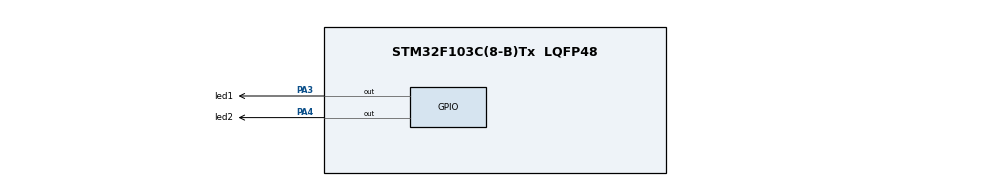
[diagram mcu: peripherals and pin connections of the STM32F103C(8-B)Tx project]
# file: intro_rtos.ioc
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Mcu.Family=STM32F1
FREERTOS.Tasks01=ledBlink01,24,128,StartDefaultTask,Default,NULL,Dynamic,NULL,NULL;ledBlink02,8,128,StartTask02,Default,NULL,Dynamic,NULL,NULL
ProjectManager.StackSize=0x400
VP_FREERTOS_VS_CMSIS_V2.Mode=CMSIS_V2
PA13.Signal=SYS_JTMS-SWDIO
ProjectManager.TargetToolchain=STM32CubeIDE
board=custom
RCC.APB2Freq_Value=8000000
PA14.Mode=Serial_Wire
PA13.Mode=Serial_Wire
Mcu.Name=STM32F103C(8-B)Tx
PA4.Signal=GPIO_Output
Mcu.Package=LQFP48
NVIC.TimeBase=TIM4_IRQn
NVIC.TimeBaseIP=TIM4
PA14.Signal=SYS_JTCK-SWCLK
ProjectManager.HeapSize=0x200
VP_SYS_VS_tim4.Mode=TIM4
NVIC.PriorityGroup=NVIC_PRIORITYGROUP_4
NVIC.TIM4_IRQn=true\:0\:0\:false\:false\:true\:false\:false\:true
RCC.APB1Freq_Value=8000000
PA4.GPIO_Label=led2
PA3.GPIO_Label=led1
PA3.Signal=GPIO_Output

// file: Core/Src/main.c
/* USER CODE BEGIN Header */
/**
  ******************************************************************************
  * @file           : main.c
  * @brief          : Main program body
  ******************************************************************************
  * @attention
  *
  * <h2><center>&copy; Copyright (c) 2021 STMicroelectronics.
  * All rights reserved.</center></h2>
  *
  * This software component is licensed by ST under BSD 3-Clause license,
  * the "License"; You may not use this file except in compliance with the
  * License. You may obtain a copy of the License at:
  *                        opensource.org/licenses/BSD-3-Clause
  *
  ******************************************************************************
  */
/* USER CODE END Header */
#include "main.h"
#include "cmsis_os.h"

/* Definitions for ledBlink01 */
osThreadId_t ledBlink01Handle;
const osThreadAttr_t ledBlink01_attributes = {
  .name = "ledBlink01",
  .stack_size = 128 * 4,
  .priority = (osPriority_t) osPriorityNormal,
};
/* Definitions for ledBlink02 */
osThreadId_t ledBlink02Handle;
const osThreadAttr_t ledBlink02_attributes = {
  .name = "ledBlink02",
  .stack_size = 128 * 4,
  .priority = (osPriority_t) osPriorityLow,
};

void SystemClock_Config(void);
static void MX_GPIO_Init(void);
void StartDefaultTask(void *argument);
void StartTask02(void *argument);

int main(void)
{

  /* MCU Configuration--------------------------------------------------------*/

  /* Reset of all peripherals, Initializes the Flash interface and the Systick. */
  HAL_Init();

  /* Configure the system clock */
  SystemClock_Config();

  /* Initialize all configured peripherals */
  MX_GPIO_Init();

  /* Init scheduler */
  osKernelInitialize();

  /* Create the thread(s) */
  /* creation of ledBlink01 */
  ledBlink01Handle = osThreadNew(StartDefaultTask, NULL, &ledBlink01_attributes);

  /* creation of ledBlink02 */
  ledBlink02Handle = osThreadNew(StartTask02, NULL, &ledBlink02_attributes);

  /* Start scheduler */
  osKernelStart();

  /* We should never get here as control is now taken by the scheduler */
  /* Infinite loop */
  while (1)
  {

  }
}

void SystemClock_Config(void)
{
  RCC_OscInitTypeDef RCC_OscInitStruct = {0};
  RCC_ClkInitTypeDef RCC_ClkInitStruct = {0};

  /** Initializes the RCC Oscillators according to the specified parameters
  * in the RCC_OscInitTypeDef structure.
  */
  RCC_OscInitStruct.OscillatorType = RCC_OSCILLATORTYPE_HSI;
  RCC_OscInitStruct.HSIState = RCC_HSI_ON;
  RCC_OscInitStruct.HSICalibrationValue = RCC_HSICALIBRATION_DEFAULT;
  RCC_OscInitStruct.PLL.PLLState = RCC_PLL_NONE;
  if (HAL_RCC_OscConfig(&RCC_OscInitStruct) != HAL_OK)
  {
    Error_Handler();
  }
  /** Initializes the CPU, AHB and APB buses clocks
  */
  RCC_ClkInitStruct.ClockType = RCC_CLOCKTYPE_HCLK|RCC_CLOCKTYPE_SYSCLK
                              |RCC_CLOCKTYPE_PCLK1|RCC_CLOCKTYPE_PCLK2;
  RCC_ClkInitStruct.SYSCLKSource = RCC_SYSCLKSOURCE_HSI;
  RCC_ClkInitStruct.AHBCLKDivider = RCC_SYSCLK_DIV1;
  RCC_ClkInitStruct.APB1CLKDivider = RCC_HCLK_DIV1;
  RCC_ClkInitStruct.APB2CLKDivider = RCC_HCLK_DIV1;

  if (HAL_RCC_ClockConfig(&RCC_ClkInitStruct, FLASH_LATENCY_0) != HAL_OK)
  {
    Error_Handler();
  }
}

static void MX_GPIO_Init(void)
{
  GPIO_InitTypeDef GPIO_InitStruct = {0};

  /* GPIO Ports Clock Enable */
  __HAL_RCC_GPIOA_CLK_ENABLE();

  /*Configure GPIO pin Output Level */
  HAL_GPIO_WritePin(GPIOA, led1_Pin|led2_Pin, GPIO_PIN_RESET);

  /*Configure GPIO pins : led1_Pin led2_Pin */
  GPIO_InitStruct.Pin = led1_Pin|led2_Pin;
  GPIO_InitStruct.Mode = GPIO_MODE_OUTPUT_PP;
  GPIO_InitStruct.Pull = GPIO_NOPULL;
  GPIO_InitStruct.Speed = GPIO_SPEED_FREQ_LOW;
  HAL_GPIO_Init(GPIOA, &GPIO_InitStruct);

}

void StartDefaultTask(void *argument)
{
  /* USER CODE BEGIN 5 */
  /* Infinite loop */
  for(;;)
  {
	HAL_GPIO_WritePin(GPIOA, GPIO_PIN_3, GPIO_PIN_SET);
    osDelay(500);
	//HAL_DELAY(500);
	HAL_GPIO_WritePin(GPIOA, GPIO_PIN_3, GPIO_PIN_RESET);
	//HAL_DELAY(500);
    osDelay(500);
  }
  /* USER CODE END 5 */
}

void StartTask02(void *argument)
{
  /* USER CODE BEGIN StartTask02 */
  /* Infinite loop */
  for(;;)
  {
	HAL_GPIO_WritePin(GPIOA, GPIO_PIN_4, GPIO_PIN_SET);
    osDelay(600);
	//HAL_DELAY(600);
	HAL_GPIO_WritePin(GPIOA, GPIO_PIN_4, GPIO_PIN_RESET);
	//HAL_DELAY(600);
    osDelay(600);
  }
  /* USER CODE END StartTask02 */
}

 /**
  * @brief  Period elapsed callback in non blocking mode
  * @note   This function is called  when TIM4 interrupt took place, inside
  * HAL_TIM_IRQHandler(). It makes a direct call to HAL_IncTick() to increment
  * a global variable "uwTick" used as application time base.
  * @param  htim : TIM handle
  * @retval None
  */
void HAL_TIM_PeriodElapsedCallback(TIM_HandleTypeDef *htim)
{
  if (htim->Instance == TIM4) {
    HAL_IncTick();
  }
}

void Error_Handler(void)
{
  __disable_irq();
  while (1)
  {
  }
}

/************************ (C) COPYRIGHT STMicroelectronics *****END OF FILE****/
